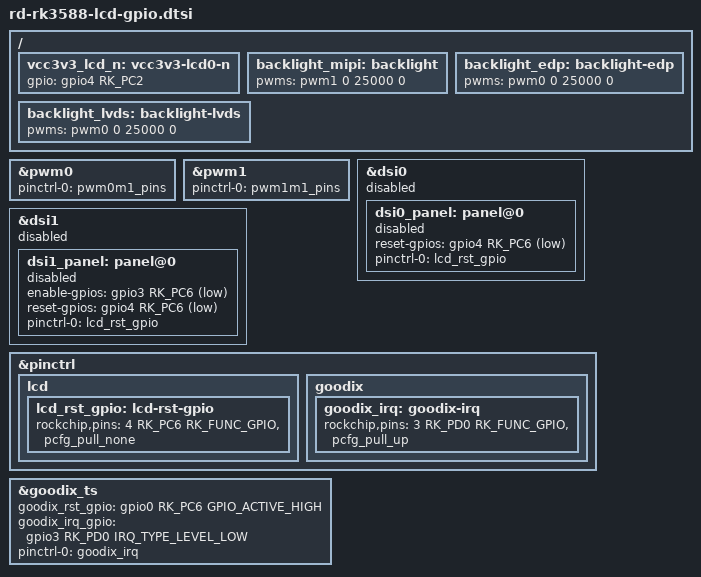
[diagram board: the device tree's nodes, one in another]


/ {
    vcc3v3_lcd_n: vcc3v3-lcd0-n {
    gpio = <&gpio4 RK_PC2 GPIO_ACTIVE_HIGH>;
  };

    backlight_mipi: backlight {
    pwms = <&pwm1 0 25000 0>;
  };

  backlight_edp: backlight-edp {
    pwms = <&pwm0 0 25000 0>;
  };

    backlight_lvds: backlight-lvds {
    pwms = <&pwm0 0 25000 0>;
  };

};


&pwm0 {
    status = "okay";
    pinctrl-0 = <&pwm0m1_pins>;
};

&pwm1 {
    status = "okay";
    pinctrl-0 = <&pwm1m1_pins>;
};

&dsi0 {
    status = "disabled";
    dsi0_panel: panel@0 {
    status = "disabled";
    reset-gpios = <&gpio4 RK_PC6 GPIO_ACTIVE_LOW>;
    pinctrl-names = "default";
    pinctrl-0 = <&lcd_rst_gpio>;
  };
};

&dsi1 {
  status = "disabled";
  dsi1_panel: panel@0 {
    status = "disabled";
    enable-gpios = <&gpio3 RK_PC6 GPIO_ACTIVE_LOW>;
    reset-gpios = <&gpio4 RK_PC6 GPIO_ACTIVE_LOW>;
    pinctrl-names = "default";
    pinctrl-0 = <&lcd_rst_gpio>;
  };
};


&pinctrl {                                                                                                               
 lcd {
   lcd_rst_gpio: lcd-rst-gpio {
     rockchip,pins = <4 RK_PC6 RK_FUNC_GPIO &pcfg_pull_none>;
   };
 };

  goodix {
    goodix_irq: goodix-irq {
      rockchip,pins = <3 RK_PD0 RK_FUNC_GPIO &pcfg_pull_up>;
    };
  };
};

&goodix_ts {
        goodix_rst_gpio = <&gpio0 RK_PC6 GPIO_ACTIVE_HIGH>;
        goodix_irq_gpio = <&gpio3 RK_PD0 IRQ_TYPE_LEVEL_LOW>;
    pinctrl-names = "default";
    pinctrl-0 = <&goodix_irq>;
};
